AUTOSAR XML (schema 4-0-3)
standard types defined: Boolean, UInt16, UInt32, UInt8
package /AUTOSAR_Platform/DataConstrs
  range DC_Boolean: raw 0..1
  range DC_UInt16: raw 0..65535
  range DC_UInt8: raw 0..255
package /PATAC/MSM/ComponentTypes
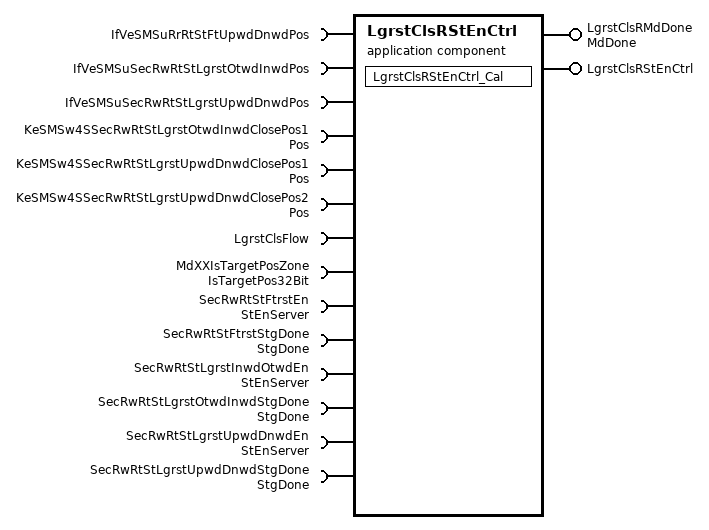
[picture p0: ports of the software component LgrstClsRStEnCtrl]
  application sw component type LgrstClsRStEnCtrl
    provide port LgrstClsRMdDone: nonqueued-sender-com-spec{data-element=MdDone/Val, init-value=0}, provided-interface=MdDone
    provide port LgrstClsRStEnCtrl: server-com-spec{operation=LgrstClsRStEnCtrl/Cal, queue-length=1}, provided-interface=LgrstClsRStEnCtrl
    14 x require port:
      IfVeSMSuRrRtStFtUpwdDnwdPos: nonqueued-receiver-com-spec{data-element=IfVeSMSuRrRtStFtUpwdDnwdPos/Val, filter=data-filter-type=ALWAYS, init-value=0}, required-interface=IfVeSMSuRrRtStFtUpwdDnwdPos
      IfVeSMSuSecRwRtStLgrstOtwdInwdPos: nonqueued-receiver-com-spec{data-element=IfVeSMSuSecRwRtStLgrstOtwdInwdPos/Val, filter=data-filter-type=ALWAYS, init-value=0}, required-interface=IfVeSMSuSecRwRtStLgrstOtwdInwdPos
      IfVeSMSuSecRwRtStLgrstUpwdDnwdPos: nonqueued-receiver-com-spec{data-element=IfVeSMSuSecRwRtStLgrstUpwdDnwdPos/Val, filter=data-filter-type=ALWAYS, init-value=0}, required-interface=IfVeSMSuSecRwRtStLgrstUpwdDnwdPos
      KeSMSw4SSecRwRtStLgrstOtwdInwdClosePos1: parameter-require-com-spec{init-value=0, parameter=Val}, required-interface=Pos
      KeSMSw4SSecRwRtStLgrstUpwdDnwdClosePos1: parameter-require-com-spec{init-value=0, parameter=Val}, required-interface=Pos
      KeSMSw4SSecRwRtStLgrstUpwdDnwdClosePos2: parameter-require-com-spec{init-value=0, parameter=Val}, required-interface=Pos
      LgrstClsFlow: client-com-spec=LgrstClsFlow/Cal, required-interface=LgrstClsFlow
      MdXXIsTargetPosZone: nonqueued-receiver-com-spec{data-element=IsTargetPos32Bit/Val, filter=data-filter-type=ALWAYS, init-value=0}, required-interface=IsTargetPos32Bit
      SecRwRtStFtrstEn: required-com-specs=[Clear, Get, Set], required-interface=StEnServer
      SecRwRtStFtrstStgDone: nonqueued-receiver-com-spec{data-element=StgDone/Val, filter=data-filter-type=ALWAYS, init-value=0}, required-interface=StgDone
      SecRwRtStLgrstInwdOtwdEn: required-com-specs=[Clear, Get, Set], required-interface=StEnServer
      SecRwRtStLgrstOtwdInwdStgDone: nonqueued-receiver-com-spec{data-element=StgDone/Val, filter=data-filter-type=ALWAYS, init-value=0}, required-interface=StgDone
      SecRwRtStLgrstUpwdDnwdEn: required-com-specs=[Clear, Get, Set], required-interface=StEnServer
      SecRwRtStLgrstUpwdDnwdStgDone: nonqueued-receiver-com-spec{data-element=StgDone/Val, filter=data-filter-type=ALWAYS, init-value=0}, required-interface=StgDone
    behavior LgrstClsRStEnCtrl_InternalBehavior
      operation invoked event OIT_LgrstClsRStEnCtrl_Cal_LgrstClsRStEnCtrl_Cal: start-on-event=LgrstClsRStEnCtrl_Cal, operation=LgrstClsRStEnCtrl.Cal
      runnable LgrstClsRStEnCtrl_Cal
        data-receive-point-by-arguments:
          7 x access:
            REC_IfVeSMSuRrRtStFtUpwdDnwdPos_Val: accessed-variable=IfVeSMSuRrRtStFtUpwdDnwdPos.Val
            REC_IfVeSMSuSecRwRtStLgrstOtwdInwdPos_Val: accessed-variable=IfVeSMSuSecRwRtStLgrstOtwdInwdPos.Val
            REC_IfVeSMSuSecRwRtStLgrstUpwdDnwdPos_Val: accessed-variable=IfVeSMSuSecRwRtStLgrstUpwdDnwdPos.Val
            REC_MdXXIsTargetPosZone_Val: accessed-variable=MdXXIsTargetPosZone.Val
            REC_SecRwRtStFtrstStgDone_Val: accessed-variable=SecRwRtStFtrstStgDone.Val
            REC_SecRwRtStLgrstOtwdInwdStgDone_Val: accessed-variable=SecRwRtStLgrstOtwdInwdStgDone.Val
            REC_SecRwRtStLgrstUpwdDnwdStgDone_Val: accessed-variable=SecRwRtStLgrstUpwdDnwdStgDone.Val
        data-send-points:
          access SEND_LgrstClsRMdDone_Val: accessed-variable=LgrstClsRMdDone.Val
        parameter access PA_KeSMSw4SSecRwRtStLgrstOtwdInwdClosePos1_Val: accessed-parameter=KeSMSw4SSecRwRtStLgrstOtwdInwdClosePos1.Val
        parameter access PA_KeSMSw4SSecRwRtStLgrstUpwdDnwdClosePos1_Val: accessed-parameter=KeSMSw4SSecRwRtStLgrstUpwdDnwdClosePos1.Val
        parameter access PA_KeSMSw4SSecRwRtStLgrstUpwdDnwdClosePos2_Val: accessed-parameter=KeSMSw4SSecRwRtStLgrstUpwdDnwdClosePos2.Val
        7 x sync call, all with timeout=0:
          SC_LgrstClsFlow_Cal: operation=LgrstClsFlow.Cal
          SC_SecRwRtStFtrstEn_Clear: operation=SecRwRtStFtrstEn.Clear
          SC_SecRwRtStFtrstEn_Set: operation=SecRwRtStFtrstEn.Set
          SC_SecRwRtStLgrstInwdOtwdEn_Clear: operation=SecRwRtStLgrstInwdOtwdEn.Clear
          SC_SecRwRtStLgrstInwdOtwdEn_Set: operation=SecRwRtStLgrstInwdOtwdEn.Set
          SC_SecRwRtStLgrstUpwdDnwdEn_Clear: operation=SecRwRtStLgrstUpwdDnwdEn.Clear
          SC_SecRwRtStLgrstUpwdDnwdEn_Set: operation=SecRwRtStLgrstUpwdDnwdEn.Set
  swc implementation LgrstClsRStEnCtrl_Implementation: behavior=LgrstClsRStEnCtrl_InternalBehavior
    code-descriptors:
      code Default: artifact-descriptors=autosar-engineering-object={short-label=Default, category=SWSRC}
package /PATAC/MSM/ModeAdjust/CalPortInterface
  parameter interface Pos
    parameter data prototype Val: sw-calibration-access=READ-WRITE, type=UInt16
package /PATAC/MSM/ModeAdjust/PortInterface
  client server interface LgrstClsFlow
    operation Cal
      13 x arg, all with server-argument-impl-policy=USE-ARGUMENT-TYPE:
        LgrstUpwdDnwdPos: type=UInt16, direction=IN
        LgrstOtwdInwdPos: type=UInt16, direction=IN
        FtUpwdDnwdPos: type=UInt16, direction=IN
        CloseDnwdPos1: type=UInt16, direction=IN
        CloseDnwdPos2: type=UInt16, direction=IN
        CloseOtwdPos1: type=UInt16, direction=IN
        LgrstInwdStgDone: type=Boolean, direction=IN
        LgrstUpwdStgDone: type=Boolean, direction=IN
        FtrstStgDone: type=Boolean, direction=IN
        Failflg: type=Boolean, direction=OUT
        LgrstInwdOtwdEn: type=Boolean, direction=OUT
        LgrstUpwdDnwdEn: type=Boolean, direction=OUT
        FtrstEn: type=Boolean, direction=OUT
  client server interface LgrstClsRStEnCtrl
    operation Cal
  client server interface StEnServer
    operation Clear
      arg data: type=UInt8, direction=IN, server-argument-impl-policy=USE-ARGUMENT-TYPE
    operation Get
      arg data: type=UInt32, direction=OUT, server-argument-impl-policy=USE-ARGUMENT-TYPE
    operation Set
      arg data: type=UInt8, direction=IN, server-argument-impl-policy=USE-ARGUMENT-TYPE
  sender receiver interface IsTargetPos32Bit: invalidation-policy{data-element=IsTargetPos32Bit/Val, handle-invalid=DONT-INVALIDATE}
    data Val: type=UInt32
  sender receiver interface MdDone: invalidation-policy{data-element=MdDone/Val, handle-invalid=DONT-INVALIDATE}
    data Val: type=UInt8
  sender receiver interface StgDone: invalidation-policy{data-element=StgDone/Val, handle-invalid=DONT-INVALIDATE}
    data Val: type=Boolean
package /PATAC/MSM/PortInterfaces
  sender receiver interface IfVeSMSuRrRtStFtUpwdDnwdPos: invalidation-policy{data-element=IfVeSMSuRrRtStFtUpwdDnwdPos/Val, handle-invalid=DONT-INVALIDATE}
    data Val: type=UInt16
  sender receiver interface IfVeSMSuSecRwRtStLgrstOtwdInwdPos: invalidation-policy{data-element=IfVeSMSuSecRwRtStLgrstOtwdInwdPos/Val, handle-invalid=DONT-INVALIDATE}
    data Val: type=UInt16
  sender receiver interface IfVeSMSuSecRwRtStLgrstUpwdDnwdPos: invalidation-policy{data-element=IfVeSMSuSecRwRtStLgrstUpwdDnwdPos/Val, handle-invalid=DONT-INVALIDATE}
    data Val: type=UInt16
